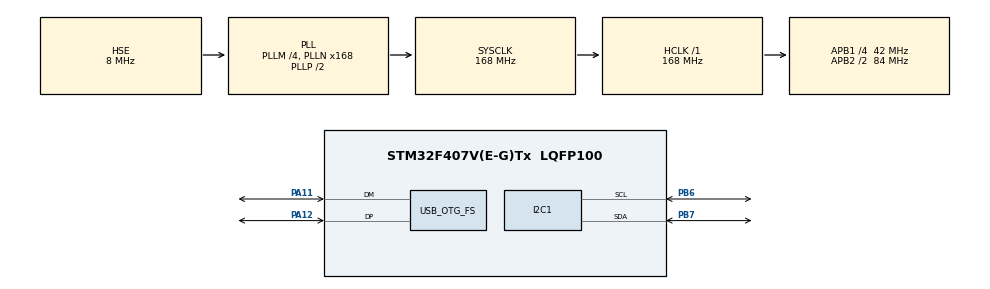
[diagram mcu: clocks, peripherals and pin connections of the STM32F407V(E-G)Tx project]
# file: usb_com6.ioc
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Mcu.Family=STM32F4
Mcu.Name=STM32F407V(E-G)Tx
Mcu.Package=LQFP100
NVIC.OTG_FS_IRQn=true\:0\:0\:false\:false\:true\:false\:true
NVIC.PriorityGroup=NVIC_PRIORITYGROUP_0
PA11.Mode=Device_Only
PA11.Signal=USB_OTG_FS_DM
PA12.Mode=Device_Only
PA12.Signal=USB_OTG_FS_DP
PB6.Mode=I2C
PB6.Signal=I2C1_SCL
PB7.Mode=I2C
PB7.Signal=I2C1_SDA
PH0-OSC_IN.Mode=HSE-External-Oscillator
PH0-OSC_IN.Signal=RCC_OSC_IN
PH1-OSC_OUT.GPIO_Label=PH1-OSC_OUT
PH1-OSC_OUT.Mode=HSE-External-Oscillator
PH1-OSC_OUT.Signal=RCC_OSC_OUT
ProjectManager.HeapSize=0x200
ProjectManager.StackSize=0x400
ProjectManager.TargetToolchain=STM32CubeIDE
RCC.48MHZClocksFreq_Value=48000000
RCC.AHBFreq_Value=168000000
RCC.APB1CLKDivider=RCC_HCLK_DIV4
RCC.APB1Freq_Value=42000000
RCC.APB1TimFreq_Value=84000000
RCC.APB2CLKDivider=RCC_HCLK_DIV2
RCC.APB2Freq_Value=84000000
RCC.APB2TimFreq_Value=168000000
RCC.CortexFreq_Value=168000000
RCC.HCLKFreq_Value=168000000
RCC.HSE_VALUE=8000000
RCC.HSI_VALUE=16000000
RCC.LSE_VALUE=32768
RCC.PLLM=4
RCC.PLLN=168
RCC.PLLQ=7
RCC.SYSCLKFreq_VALUE=168000000
RCC.SYSCLKSource=RCC_SYSCLKSOURCE_PLLCLK
RCC.VCOOutputFreq_Value=336000000
USB_DEVICE.CLASS_NAME_FS=CDC
USB_DEVICE.VirtualMode-CDC_FS=Cdc
USB_DEVICE.VirtualModeFS=Cdc_FS
USB_OTG_FS.VirtualMode=Device_Only
VP_USB_DEVICE_VS_USB_DEVICE_CDC_FS.Mode=CDC_FS
board=STM32F407G-DISC1

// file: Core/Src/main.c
/* USER CODE BEGIN Header */
/**
  ******************************************************************************
  * @file           : main.c
  * @brief          : Main program body
  ******************************************************************************
  * @attention
  *
  * <h2><center>&copy; Copyright (c) 2021 STMicroelectronics.
  * All rights reserved.</center></h2>
  *
  * This software component is licensed by ST under Ultimate Liberty license
  * SLA0044, the "License"; You may not use this file except in compliance with
  * the License. You may obtain a copy of the License at:
  *                             www.st.com/SLA0044
  *
  ******************************************************************************
  */
/* USER CODE END Header */
#include "main.h"
#include "i2c.h"
#include "usb_device.h"
#include "usbd_cdc_if.h"
#include "gpio.h"
#include "keypad.h"
#include "DISPLAY_WH1602B_4Bit.h"

I2C_HandleTypeDef hi2c1;

/* USER CODE BEGIN PV */
char str_tx[21];
char str_rx[21];
/* USER CODE END PV */

void SystemClock_Config(void);

int main(void)
{
  /* USER CODE BEGIN 1 */
	uint8_t i = 0;
  /* USER CODE END 1 */

  /* MCU Configuration--------------------------------------------------------*/

  /* Reset of all peripherals, Initializes the Flash interface and the Systick. */
  HAL_Init();

  /* Configure the system clock */
  SystemClock_Config();

  /* Initialize all configured peripherals */
  MX_GPIO_Init();
  MX_I2C1_Init();
  MX_USB_DEVICE_Init();
  /* USER CODE BEGIN 2 */
	sprintf(str_tx, "HWorld\r\n");

//	Display_init_GPIO();
//	Display_Init();
//	Display_Write_Ins(GO_TO_START_FIRST_LINE);
//	Display_Write_Data('H');
//	HAL_Delay(500);

	  setup_GPIO_for_keypad();

	  setup_Display();
	  Display_Write_Ins(GO_TO_START_FIRST_LINE);
//	  Display_Write_Data('M');
//	  Display_Write_Data('E');

  /* USER CODE END 2 */

  /* Infinite loop */
  while (1)
  {

    /* USER CODE BEGIN 3 */
	  Keypad_loop();

//	  //Transmit data through COM6 to PC
//	  CDC_Transmit_FS((unsigned char*)str_tx, strlen(str_tx));
//	  HAL_Delay(500);
//
//
//	  //Receive data through COM6 to Display from PC
//
//	  Display_Write_Ins(GO_TO_START_FIRST_LINE);
//	  for (int i=0; i<strlen(str_rx); ++i) {
//	  		  Display_Write_Data(str_rx[i]);
//	  }
//	  for(i=1;i<((uint8_t)(16-strlen(str_rx)));i++)
//	  		  Display_Write_Data(' ');
//	  HAL_Delay(500);

  }
  /* USER CODE END 3 */
}

void SystemClock_Config(void)
{
  RCC_OscInitTypeDef RCC_OscInitStruct = {0};
  RCC_ClkInitTypeDef RCC_ClkInitStruct = {0};

  /** Configure the main internal regulator output voltage
  */
  __HAL_RCC_PWR_CLK_ENABLE();
  __HAL_PWR_VOLTAGESCALING_CONFIG(PWR_REGULATOR_VOLTAGE_SCALE1);
  /** Initializes the RCC Oscillators according to the specified parameters
  * in the RCC_OscInitTypeDef structure.
  */
  RCC_OscInitStruct.OscillatorType = RCC_OSCILLATORTYPE_HSE;
  RCC_OscInitStruct.HSEState = RCC_HSE_ON;
  RCC_OscInitStruct.PLL.PLLState = RCC_PLL_ON;
  RCC_OscInitStruct.PLL.PLLSource = RCC_PLLSOURCE_HSE;
  RCC_OscInitStruct.PLL.PLLM = 4;
  RCC_OscInitStruct.PLL.PLLN = 168;
  RCC_OscInitStruct.PLL.PLLP = RCC_PLLP_DIV2;
  //  RCC_OscInitStruct.PLL.PLLQ = 7;
  RCC_OscInitStruct.PLL.PLLQ = 7;
  if (HAL_RCC_OscConfig(&RCC_OscInitStruct) != HAL_OK)
  {
    Error_Handler();
  }
  /** Initializes the CPU, AHB and APB buses clocks
  */
  RCC_ClkInitStruct.ClockType = RCC_CLOCKTYPE_HCLK|RCC_CLOCKTYPE_SYSCLK
                              |RCC_CLOCKTYPE_PCLK1|RCC_CLOCKTYPE_PCLK2;
  RCC_ClkInitStruct.SYSCLKSource = RCC_SYSCLKSOURCE_PLLCLK;
  RCC_ClkInitStruct.AHBCLKDivider = RCC_SYSCLK_DIV1;
  RCC_ClkInitStruct.APB1CLKDivider = RCC_HCLK_DIV4;
  RCC_ClkInitStruct.APB2CLKDivider = RCC_HCLK_DIV2;

  if (HAL_RCC_ClockConfig(&RCC_ClkInitStruct, FLASH_LATENCY_5) != HAL_OK)
  {
    Error_Handler();
  }

  HAL_SYSTICK_Config(HAL_RCC_GetHCLKFreq()/1000);

  HAL_SYSTICK_CLKSourceConfig(SYSTICK_CLKSOURCE_HCLK);

    /* SysTick_IRQn interrupt configuration */
  HAL_NVIC_SetPriority(SysTick_IRQn, 0, 0);

}

void Error_Handler(void)
{
  __disable_irq();
  while (1)
  {
  }
}

/************************ (C) COPYRIGHT STMicroelectronics *****END OF FILE****/
